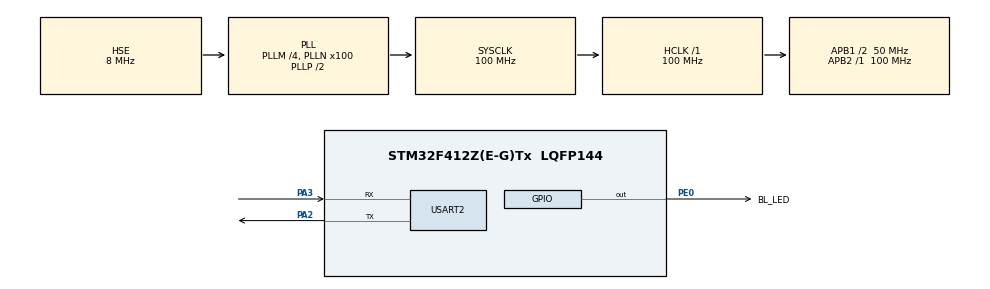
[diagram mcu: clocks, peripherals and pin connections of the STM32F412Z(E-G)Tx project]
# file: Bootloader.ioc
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Mcu.Family=STM32F4
Mcu.Name=STM32F412Z(E-G)Tx
Mcu.Package=LQFP144
NVIC.PriorityGroup=NVIC_PRIORITYGROUP_4
PA13.Mode=Serial_Wire
PA13.Signal=SYS_JTMS-SWDIO
PA14.Mode=Serial_Wire
PA14.Signal=SYS_JTCK-SWCLK
PA2.Mode=Asynchronous
PA2.Signal=USART2_TX
PA3.Mode=Asynchronous
PA3.Signal=USART2_RX
PC14-OSC32_IN.Mode=LSE-External-Oscillator
PC14-OSC32_IN.Signal=RCC_OSC32_IN
PC15-OSC32_OUT.Mode=LSE-External-Oscillator
PC15-OSC32_OUT.Signal=RCC_OSC32_OUT
PE0.GPIO_Label=BL_LED
PE0.PinState=GPIO_PIN_SET
PE0.Signal=GPIO_Output
PH0\ -\ OSC_IN.Mode=HSE-External-Clock-Source
PH0\ -\ OSC_IN.Signal=RCC_OSC_IN
PH1\ -\ OSC_OUT.Mode=HSE-External-Clock-Source
PH1\ -\ OSC_OUT.Signal=RCC_OSC_OUT
ProjectManager.HeapSize=0x200
ProjectManager.StackSize=0x400
ProjectManager.TargetToolchain=STM32CubeIDE
RCC.AHBFreq_Value=100000000
RCC.APB1CLKDivider=RCC_HCLK_DIV2
RCC.APB1Freq_Value=50000000
RCC.APB1TimFreq_Value=100000000
RCC.APB2Freq_Value=100000000
RCC.APB2TimFreq_Value=100000000
RCC.CortexFreq_Value=100000000
RCC.HCLKFreq_Value=100000000
RCC.HSE_VALUE=8000000
RCC.PLLM=4
RCC.PLLN=100
RCC.PLLSourceVirtual=RCC_PLLSOURCE_HSE
RCC.SYSCLKFreq_VALUE=100000000
RCC.SYSCLKSource=RCC_SYSCLKSOURCE_PLLCLK
RCC.USBFreq_Value=100000000
RCC.VCOOutputFreq_Value=200000000
USART2.VirtualMode=VM_ASYNC
VP_CRC_VS_CRC.Mode=CRC_Activate
board=custom

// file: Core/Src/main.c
/* USER CODE BEGIN Header */
/**
 ******************************************************************************
 * @file           : main.c
 * @brief          : Main program body
 ******************************************************************************
 * @attention
 *
 * Copyright (c) 2023 STMicroelectronics.
 * All rights reserved.
 *
 * This software is licensed under terms that can be found in the LICENSE file
 * in the root directory of this software component.
 * If no LICENSE file comes with this software, it is provided AS-IS.
 *
 ******************************************************************************
 */
/* USER CODE END Header */
#include "main.h"

/* USER CODE BEGIN Includes */
#include <stdio.h>
#include <string.h>
#include <stdbool.h>
#include "debug.h"
#include "bl_update_app.h"
/* USER CODE END Includes */

CRC_HandleTypeDef hcrc;

UART_HandleTypeDef huart2;

/* USER CODE BEGIN PV */
const uint8_t BL_Version[2] = { MAJOR, MINOR };
/* USER CODE END PV */

void SystemClock_Config(void);
static void MX_GPIO_Init(void);
static void MX_USART2_UART_Init(void);
static void MX_CRC_Init(void);

int main(void)
{

  /* MCU Configuration--------------------------------------------------------*/

  /* Reset of all peripherals, Initializes the Flash interface and the Systick. */
  HAL_Init();

  /* Configure the system clock */
  SystemClock_Config();

  /* Initialize all configured peripherals */
  MX_GPIO_Init();
  MX_USART2_UART_Init();
  MX_CRC_Init();
  /* USER CODE BEGIN 2 */
	DEBUG_PRINT("\tBootloader %d.%d started ...", BL_Version[0], BL_Version[1]);

	check_need_for_download(); // check if there are requests from Host

  /* USER CODE END 2 */

  /* Infinite loop */
while (1) {

}
}

void SystemClock_Config(void)
{
  RCC_OscInitTypeDef RCC_OscInitStruct = {0};
  RCC_ClkInitTypeDef RCC_ClkInitStruct = {0};

  /** Configure the main internal regulator output voltage
  */
  __HAL_RCC_PWR_CLK_ENABLE();
  __HAL_PWR_VOLTAGESCALING_CONFIG(PWR_REGULATOR_VOLTAGE_SCALE1);

  /** Initializes the RCC Oscillators according to the specified parameters
  * in the RCC_OscInitTypeDef structure.
  */
  RCC_OscInitStruct.OscillatorType = RCC_OSCILLATORTYPE_HSE;
  RCC_OscInitStruct.HSEState = RCC_HSE_BYPASS;
  RCC_OscInitStruct.PLL.PLLState = RCC_PLL_ON;
  RCC_OscInitStruct.PLL.PLLSource = RCC_PLLSOURCE_HSE;
  RCC_OscInitStruct.PLL.PLLM = 4;
  RCC_OscInitStruct.PLL.PLLN = 100;
  RCC_OscInitStruct.PLL.PLLP = RCC_PLLP_DIV2;
  RCC_OscInitStruct.PLL.PLLQ = 2;
  RCC_OscInitStruct.PLL.PLLR = 2;
  if (HAL_RCC_OscConfig(&RCC_OscInitStruct) != HAL_OK)
  {
    Error_Handler();
  }

  /** Initializes the CPU, AHB and APB buses clocks
  */
  RCC_ClkInitStruct.ClockType = RCC_CLOCKTYPE_HCLK|RCC_CLOCKTYPE_SYSCLK
                              |RCC_CLOCKTYPE_PCLK1|RCC_CLOCKTYPE_PCLK2;
  RCC_ClkInitStruct.SYSCLKSource = RCC_SYSCLKSOURCE_PLLCLK;
  RCC_ClkInitStruct.AHBCLKDivider = RCC_SYSCLK_DIV1;
  RCC_ClkInitStruct.APB1CLKDivider = RCC_HCLK_DIV2;
  RCC_ClkInitStruct.APB2CLKDivider = RCC_HCLK_DIV1;

  if (HAL_RCC_ClockConfig(&RCC_ClkInitStruct, FLASH_LATENCY_3) != HAL_OK)
  {
    Error_Handler();
  }
}

static void MX_CRC_Init(void)
{

  hcrc.Instance = CRC;
  if (HAL_CRC_Init(&hcrc) != HAL_OK)
  {
    Error_Handler();
  }

}

static void MX_USART2_UART_Init(void)
{

  huart2.Instance = USART2;
  huart2.Init.BaudRate = 115200;
  huart2.Init.WordLength = UART_WORDLENGTH_8B;
  huart2.Init.StopBits = UART_STOPBITS_1;
  huart2.Init.Parity = UART_PARITY_NONE;
  huart2.Init.Mode = UART_MODE_TX_RX;
  huart2.Init.HwFlowCtl = UART_HWCONTROL_NONE;
  huart2.Init.OverSampling = UART_OVERSAMPLING_16;
  if (HAL_UART_Init(&huart2) != HAL_OK)
  {
    Error_Handler();
  }

}

static void MX_GPIO_Init(void)
{
  GPIO_InitTypeDef GPIO_InitStruct = {0};

  /* GPIO Ports Clock Enable */
  __HAL_RCC_GPIOC_CLK_ENABLE();
  __HAL_RCC_GPIOH_CLK_ENABLE();
  __HAL_RCC_GPIOA_CLK_ENABLE();
  __HAL_RCC_GPIOE_CLK_ENABLE();

  /*Configure GPIO pin Output Level */
  HAL_GPIO_WritePin(BL_LED_GPIO_Port, BL_LED_Pin, GPIO_PIN_SET);

  /*Configure GPIO pin : BL_LED_Pin */
  GPIO_InitStruct.Pin = BL_LED_Pin;
  GPIO_InitStruct.Mode = GPIO_MODE_OUTPUT_PP;
  GPIO_InitStruct.Pull = GPIO_NOPULL;
  GPIO_InitStruct.Speed = GPIO_SPEED_FREQ_LOW;
  HAL_GPIO_Init(BL_LED_GPIO_Port, &GPIO_InitStruct);

}

/* USER CODE BEGIN 4 */

int _write(int file, char *ptr, int len) {
/* Implement your write code here, this is used by puts and printf for example */
int i = 0;
for (i = 0; i < len; i++)
	ITM_SendChar((*ptr++));
return len;
}

//#ifdef __GNUC__
//  /* With GCC, small printf (option LD Linker->Libraries->Small printf
//     set to 'Yes') calls __io_putchar() */
//int __io_putchar(int ch)
//#else
//int fputc(int ch, FILE *f)
//#endif /* __GNUC__ */
//{
//  /* Place your implementation of fputc here */
//  /* e.g. write a character to the UART3 and Loop until the end of transmission */
//  HAL_UART_Transmit(&huart2, (uint8_t *)&ch, 1, HAL_MAX_DELAY);
//  return ch;
//}

/* USER CODE END 4 */

void Error_Handler(void)
{
__disable_irq();
while (1) {
}
}
